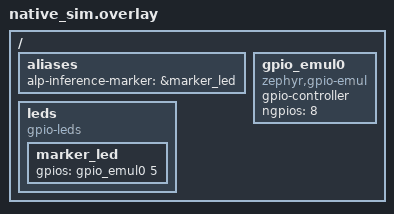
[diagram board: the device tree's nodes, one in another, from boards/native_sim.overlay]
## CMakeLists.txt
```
# SPDX-License-Identifier: Apache-2.0
cmake_minimum_required(VERSION 3.20)

find_package(Zephyr REQUIRED HINTS $ENV{ZEPHYR_BASE})
project(alp_sdk_inference_marker_test LANGUAGES C)

target_sources(app PRIVATE src/main.c)
```

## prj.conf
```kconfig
# SPDX-License-Identifier: Apache-2.0
CONFIG_ZTEST=y
CONFIG_ALP_SDK=y
CONFIG_ALP_SOC_ALIF_ENSEMBLE_E7=y
CONFIG_ALP_SDK_INFERENCE_SW_FALLBACK=y
CONFIG_GPIO=y
CONFIG_GPIO_EMUL=y
CONFIG_ALP_INFERENCE_MARKER=y
CONFIG_THREAD_LOCAL_STORAGE=y
```

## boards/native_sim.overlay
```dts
/* SPDX-License-Identifier: Apache-2.0 */
#include <zephyr/dt-bindings/gpio/gpio.h>

/ {
	aliases {
		alp-inference-marker = &marker_led;
	};

	gpio_emul0: gpio_emul0 {
		compatible = "zephyr,gpio-emul";
		status = "okay";
		gpio-controller;
		#gpio-cells = <2>;
		ngpios = <8>;
	};

	leds {
		compatible = "gpio-leds";
		marker_led: marker_led {
			gpios = <&gpio_emul0 5 GPIO_ACTIVE_HIGH>;
		};
	};
};
```

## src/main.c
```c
/* SPDX-License-Identifier: Apache-2.0
 *
 * CONFIG_ALP_INFERENCE_MARKER: the `alp-inference-marker` pin is high
 * while a backend's invoke() runs and low before and after, on both the
 * success and the error path.  A fabricated handle carries an invoke()
 * that samples the emulated pin.
 */

#include <zephyr/device.h>
#include <zephyr/drivers/gpio.h>
#include <zephyr/ztest.h>

#include <alp/inference.h>

#include "../../../../src/backends/inference/inference_ops.h"
#include "alp_slot_claim.h"

static const struct gpio_dt_spec marker = GPIO_DT_SPEC_GET(DT_ALIAS(alp_inference_marker), gpios);

static int seen_during_invoke = -1;

static alp_status_t invoke_ok(alp_inference_backend_state_t *state)
{
	(void)state;
	seen_during_invoke = gpio_pin_get_dt(&marker);
	return ALP_OK;
}

static alp_status_t invoke_err(alp_inference_backend_state_t *state)
{
	(void)state;
	seen_during_invoke = gpio_pin_get_dt(&marker);
	return ALP_ERR_IO;
}

static const alp_inference_ops_t ops_ok  = { .invoke = invoke_ok };
static const alp_inference_ops_t ops_err = { .invoke = invoke_err };

/* gpio-emul only reflects a driven level on a pin that is also an input;
 * re-configure the marker pin as both, still parked inactive. */
static void before(void *fixture)
{
	(void)fixture;
	zassert_ok(gpio_pin_configure_dt(&marker, GPIO_OUTPUT_INACTIVE | GPIO_INPUT));
}

ZTEST_SUITE(alp_inference_marker, NULL, NULL, before, NULL, NULL);

static void check(const alp_inference_ops_t *ops, alp_status_t want)
{
	struct alp_inference fake = {
		.state                  = { .ops = ops },
		.lifecycle              = ALP_HANDLE_LC_OPEN,
		.last_invoke_latency_us = UINT32_MAX,
		.in_use                 = true,
	};
	seen_during_invoke = -1;
	zassert_equal(gpio_pin_get_dt(&marker), 0, "marker must idle low");
	zassert_equal(alp_inference_invoke(&fake), want);
	zassert_equal(seen_during_invoke, 1, "marker must be high inside invoke()");
	zassert_equal(gpio_pin_get_dt(&marker), 0, "marker must drop after invoke()");
}

ZTEST(alp_inference_marker, test_high_during_invoke_success)
{
	check(&ops_ok, ALP_OK);
}

ZTEST(alp_inference_marker, test_low_after_invoke_error)
{
	check(&ops_err, ALP_ERR_IO);
}
```
